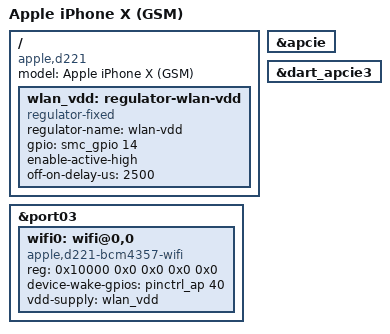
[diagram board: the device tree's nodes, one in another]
// SPDX-License-Identifier: GPL-2.0+ OR MIT
/*
 * Apple iPhone X (GSM), D221, iPhone10,6 (A1901)
 * Copyright (c) 2022, Konrad Dybcio <konradybcio@kernel.org>
 */

/dts-v1/;

#include "t8015-x.dtsi"

/ {
	compatible = "apple,d221", "apple,t8015", "apple,arm-platform";
	model = "Apple iPhone X (GSM)";

	/* The BCM4357's REG_ON: SMC PMU GPIO 14 ("gP0e"), active-high. */
	wlan_vdd: regulator-wlan-vdd {
		compatible = "regulator-fixed";
		regulator-name = "wlan-vdd";
		gpio = <&smc_gpio 14 GPIO_ACTIVE_HIGH>;
		enable-active-high;
		off-on-delay-us = <2500>;
	};
};

&apcie {
	status = "okay";
};

&dart_apcie3 {
	status = "okay";
};

&port03 {
	wifi0: wifi@0,0 {
		compatible = "apple,d221-bcm4357-wifi", "pci14e4,440a";
		reg = <0x10000 0x0 0x0 0x0 0x0>;
		device-wake-gpios = <&pinctrl_ap 40 GPIO_ACTIVE_HIGH>;
		vdd-supply = <&wlan_vdd>;
	};
};
